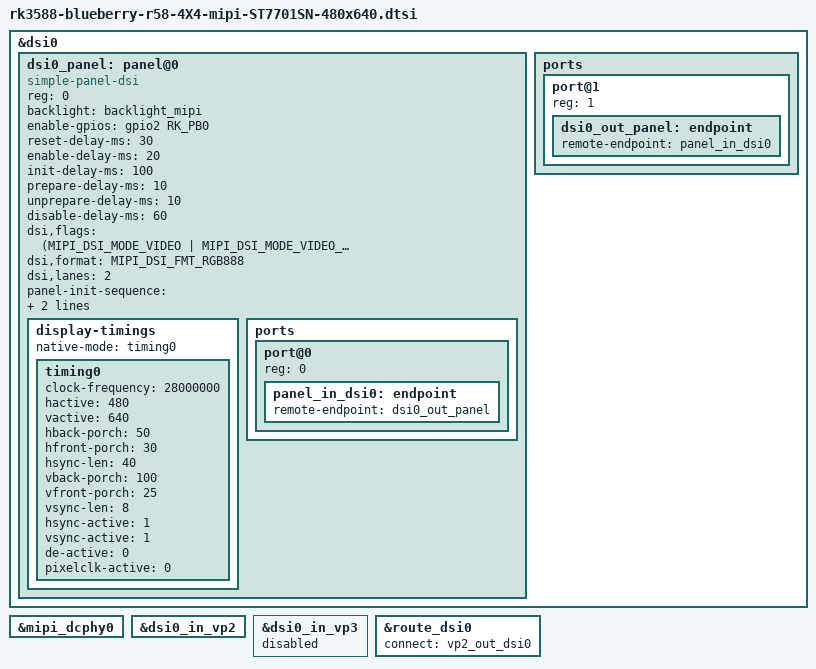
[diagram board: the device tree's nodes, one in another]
// SPDX-License-Identifier: (GPL-2.0+ OR MIT)
/*
 * Copyright (c) 2021 Rockchip Electronics Co., Ltd.
 *
 */

#include "dt-bindings/usb/pd.h"



&dsi0 {
	status = "okay";
	//rockchip,lane-rate = <1000>;
	dsi0_panel: panel@0 {
		status = "okay";
		compatible = "simple-panel-dsi";
		reg = <0>;
		backlight = <&backlight_mipi>;
		//power-supply = <&vcc3v3_mipi_lcd_power>;
		//reset-gpios =  <&gpio3 RK_PC4 GPIO_ACTIVE_LOW>; 
		enable-gpios = <&gpio2 RK_PB0 GPIO_ACTIVE_HIGH>;
		reset-delay-ms = <30>;
		enable-delay-ms = <20>;
		init-delay-ms = <100>;
		prepare-delay-ms = <10>;
		unprepare-delay-ms = <10>;
		disable-delay-ms = <60>;
		dsi,flags = <(MIPI_DSI_MODE_VIDEO | MIPI_DSI_MODE_VIDEO_BURST |
			MIPI_DSI_MODE_LPM | MIPI_DSI_MODE_EOT_PACKET)>;
		dsi,format = <MIPI_DSI_FMT_RGB888>;
		dsi,lanes  = <2>;

		panel-init-sequence = [
			29 00 06 FF 77 01 00 00 13
			23 00 02 EF 08
			29 00 06 FF 77 01 00 00 10
			29 00 03 C0 4F 00
			29 00 03 C1 10 02
			29 00 03 C2 07 02
			23 00 02 CC 10
			29 00 11 B0 00 10 17 0D 11 06 05 08 07 1F 04 11 0E 29 30 1F
			29 00 11 B1 00 0D 14 0E 11 06 04 08 08 20 05 13 13 26 30 1F
			29 00 06 FF 77 01 00 00 11
			23 00 02 B0 65
			23 00 02 B1 71
			23 00 02 B2 82
			23 00 02 B3 80
			23 00 02 B5 42
			23 00 02 B7 85
			23 00 02 B8 20			
			23 00 02 C0 09
			23 00 02 C1 78
			23 00 02 C2 78
			23 00 02 D0 88
			23 00 02 EE 42
			29 00 04 E0 00 00 02
			29 00 0C E1 04 A0 06 A0 05 A0 07 A0 00 44 44
			29 00 0D E2 00 00 00 00 00 00 00 00 00 00 00 00
			29 00 05 E3 00 00 22 22
			29 00 03 E4 44 44
			29 00 11 E5 0C 90 A0 A0 0E 92 A0 A0 08 8C A0 A0 0A 8E A0 A0
			29 00 05 E6 00 00 22 22
			29 00 03 E7 44 44
			29 00 11 E8 0D 91 A0 A0 0F 93 A0 A0 09 8D A0 A0 0B 8F A0 A0
			29 00 08 EB 00 00 E4 E4 44 00 40
			29 00 11 ED FF F5 47 6F 0B A1 AB FF FF BA 1A B0 F6 74 5F FF
			29 00 07 EF 08 08 08 40 3F 64
			29 00 06 FF 77 01 00 00 00
			29 00 06 FF 77 01 00 00 13
			29 00 03 E6 16 7C
			29 00 03 E8 00 0E
			29 00 06 FF 77 01 00 00 00
			05 78 01 11
			29 00 06 FF 77 01 00 00 13

			29 10 03 E8 00 0C
			29 10 03 E8 00 00
			29 00 06 FF 77 01 00 00 00
			05 00 01 29
			23 00 02 35 00

		];
		/*  //可以显示但有网格  2.8IPS_ADS(480X640)_ST7701S_FW(Customer)-190802.ini
				panel-init-sequence = [
			29 00 06 FF 77 01 00 00 13
			23 00 02 EF 08
			29 00 06 FF 77 01 00 00 10
			29 00 03 C0 4F 00
			29 00 03 C1 10 0C
			29 00 03 C2 01 14
			23 00 02 CC 10
			29 00 11 B0 0A 18 1E 12 16 0C 0E 0D 0C 29 06 14 13 29 33 1C
			29 00 11 B1 0A 19 21 0A 0C 00 0C 03 03 23 01 0E 0C 27 2B 1C
			29 00 06 FF 77 01 00 00 11
			23 00 02 B0 5D
			23 00 02 B1 4B
			23 00 02 B2 84
			23 00 02 B3 80
			23 00 02 B5 4D
			23 00 02 B7 85
			23 00 02 B8 20			
			23 00 02 C1 78
			23 00 02 C2 78
			23 00 02 D0 88
			29 00 04 E0 00 00 02
			29 00 0C E1 06 A0 08 A0 05 A0 07 A0 00 44 44
			29 00 0D E2 20 20 44 44 96 A0 00 00 96 A0 00 00
			29 00 05 E3 00 00 22 22
			29 00 03 E4 44 44
			29 00 11 E5 0D 91 A0 A0 0F 93 A0 A0 09 8D A0 A0 0B 8F A0 A0
			29 00 05 E6 00 00 22 22
			29 00 03 E7 44 44
			29 00 11 E8 0C 90 A0 A0 0E 92 A0 A0 08 8C A0 0A 0A 8E A0 A0
			29 00 03 E9 36 00
			29 00 08 EB 00 00 E4 E4 44 88 40
			29 00 11 ED FF 45 67 FA 01 2B CF FF FF FC B2 10 AF 76 54 FF
			29 00 07 EF 10 0D 04 08 3F 1F
			05 78 01 11
			23 00 02 36 00
			05 00 01 29
			23 00 02 35 00

		];*/

/*  //可以点亮，但是花屏
		panel-init-sequence = [
			29 00 06 FF 77 01 00 00 13
			23 00 02 EF 08
			29 00 06 FF 77 01 00 00 10
			29 00 03 C0 4F 00
			29 00 03 C1 10 02
			29 00 03 C2 07 02
			23 00 02 CC 10
			29 00 11 B0 00 10 17 0D 11 06 05 08 07 1F 04 11 0E 29 30 1F
			29 00 11 B1 00 0D 14 0E 11 06 04 08 08 20 05 13 13 26 30 1F
			29 00 06 FF 77 01 00 00 11
			23 00 02 B0 65
			23 00 02 B1 71
			23 00 02 B2 82
			23 00 02 B3 80
			23 00 02 B5 42
			23 00 02 B7 85
			23 00 02 B8 20			
			23 00 02 C0 09
			23 00 02 C1 78
			23 00 02 C2 78
			23 00 02 D0 88
			23 00 02 EE 42
			29 00 04 E0 00 00 02
			29 00 0C E1 04 A0 06 A0 05 A0 07 A0 00 44 44
			29 00 0D E2 00 00 00 00 00 00 00 00 00 00 00 00
			29 00 05 E3 00 00 22 22
			29 00 03 E4 44 44
			29 00 11 E5 0C 90 A0 A0 0E 92 A0 A0 08 8C A0 A0 0A 8E A0 A0
			29 00 05 E6 00 00 22 22
			29 00 03 E7 44 44
			29 00 11 E8 0D 91 A0 A0 0F 93 A0 A0 09 8D A0 A0 0B 8F A0 A0
			29 00 08 EB 00 00 E4 E4 44 00 40
			29 00 11 ED FF F5 47 6F 0B A1 AB FF FF BA 1A B0 F6 74 5F FF
			29 00 07 EF 08 08 08 40 3F 64
			29 00 06 FF 77 01 00 00 00
			29 00 06 FF 77 01 00 00 13
			29 00 03 E6 16 7C
			29 00 03 E8 00 0E
			29 00 06 FF 77 01 00 00 00
			05 78 01 11
			29 00 06 FF 77 01 00 00 13

			29 10 03 E8 00 0C
			29 10 03 E8 00 00
			29 00 06 FF 77 01 00 00 00
			05 00 01 29
			23 00 02 35 00
		];
		*/
/*
		panel-init-sequence = [
			29 00 06 FF 77 01 00 00 13
			23 00 02 EF 08
			29 00 06 FF 77 01 00 00 10
			29 00 03 C0 4F 00
			29 00 03 C1 10 02
			29 00 03 C2 07 02
			23 00 02 CC 10
			29 00 11 B0 00 10 17 0D 11 06 05 08 07 1F 04 11 0E 29 30 1F
			29 00 11 B1 00 0D 14 0E 11 06 04 08 08 20 05 13 13 26 30 1F
			29 00 06 FF 77 01 00 00 11
			23 00 02 B0 65
			23 00 02 B1 71
			23 00 02 B2 82
			23 00 02 B3 80
			23 00 02 B5 42
			23 00 02 B7 85
			23 00 02 B8 20			
			23 00 02 C0 09
			23 00 02 C1 78
			23 00 02 C2 78
			23 00 02 D0 88
			23 00 02 EE 42
			29 00 04 E0 00 00 02
			29 00 0C E1 04 A0 06 A0 05 A0 07 A0 00 44 44
			29 00 0D E2 00 00 00 00 00 00 00 00 00 00 00 00
			29 00 05 E3 00 00 22 22
			29 00 03 E4 44 44
			29 00 11 E5 0C 90 A0 A0 0E 92 A0 A0 08 8C A0 A0 0A 8E A0 A0
			29 00 05 E6 00 00 22 22
			29 00 03 E7 44 44
			29 00 11 E8 0D 91 A0 A0 0F 93 A0 A0 09 8D A0 A0 0B 8F A0 A0
			29 00 08 EB 00 00 E4 E4 44 00 40
			29 00 11 ED FF F5 47 6F 0B A1 AB FF FF BA 1A B0 F6 74 5F FF
			29 00 07 EF 08 08 08 40 3F 64
			29 00 06 FF 77 01 00 00 00
			29 00 06 FF 77 01 00 00 13
			29 00 03 E6 16 7C
			29 00 03 E8 00 0E
			29 00 06 FF 77 01 00 00 00
			05 78 01 11
			29 00 06 FF 77 01 00 00 13

			29 10 03 E8 00 0C
			29 10 03 E8 00 00
			29 00 06 FF 77 01 00 00 00
			05 00 01 29
			23 00 02 35 00
		];
		*/
/*
		panel-init-sequence = [
			29 00 06 FF 77 01 00 00 13
			29 00 03 E8 00 0E
			29 00 06 FF 77 01 00 00 00
			05 78 01 11
			29 00 06 FF 77 01 00 00 13
			29 0A 03 E8 00 0C
			29 00 03 E8 00 00
			29 00 06 FF 77 01 00 00 00
			29 00 06 FF 77 01 00 00 10
			29 00 03 C0 4F 00
			29 00 03 C1 07 02
			29 00 03 C2 31 05
			23 00 02 C6 01
			23 00 02 CC 38
			29 00 11 B0 00 0A 11 0C 10 05 00 08 08 1F 07 13 10 A9 30 18
			29 00 11 B1 00 0B 11 0D 0F 05 02 07 06 20 05 15 13 A9 30 18
			29 00 06 FF 77 01 00 00 11
			23 00 02 B0 53
			23 00 02 B1 60
			23 00 02 B2 87
			23 00 02 B3 80
			23 00 02 B5 49
			23 00 02 B7 85
			23 00 02 B8 21
			23 00 02 C1 78
			23 78 02 C2 78
			29 00 04 E0 00 00 02
			29 00 0C E1 03 A0 00 00 02 A0 00 00 00 33 33
			29 00 0D E2 22 22 33 33 88 A0 00 00 87 A0 00 00
			29 00 05 E3 00 00 22 22
			29 00 03 E4 44 44
			29 00 11 E5 04 84 A0 A0 06 86 A0 A0 08 88 A0 A0 0A 8A A0 A0
			29 00 05 E6 00 00 22 22
			29 00 03 E7 44 44
			29 00 11 E8 03 83 A0 A0 05 85 A0 A0 07 87 A0 A0 09 89 A0 A0
			29 00 08 EB 00 01 E4 E4 88 00 40
			29 00 03 EC 3C 01
			29 00 11 ED AB 89 76 54 02 FF FF FF FF FF FF 20 45 67 98 BA
			29 00 07 EF 08 08 08 08 3F 1F
			29 00 06 FF 77 01 00 00 00
			05 14 01 29
		];
*/
		panel-exit-sequence = [
		];

		display-timings {
			native-mode = <&timing0>;
			timing0: timing0 {
				clock-frequency = <28000000>;  //159391260  159747840
				hactive = <480>;
				vactive = <640>; 
				hback-porch = <50>; //50
				hfront-porch = <30>;//30
				hsync-len = <40>;//40
				vback-porch = <100>;//100
				vfront-porch = <25>;//25
				vsync-len = <8>;//8
				hsync-active = <1>;
				vsync-active = <1>;
				de-active = <0>;
				pixelclk-active = <0>;
				};
		};

		ports {
			#address-cells = <1>;
			#size-cells = <0>;

			port@0 {
				reg = <0>;
				panel_in_dsi0: endpoint {
					remote-endpoint = <&dsi0_out_panel>;
				};
			};
		};
	};

		ports {
			#address-cells = <1>;
			#size-cells = <0>;

			port@1 {
				reg = <1>;
				dsi0_out_panel: endpoint {
					remote-endpoint = <&panel_in_dsi0>;
				};
			};
		};
	
};

&dsi0 {
	status = "okay";
};

&mipi_dcphy0 {
	status = "okay";
};

&dsi0_in_vp2 {
	status = "okay";
};

&dsi0_in_vp3 {
	status = "disabled";
};

&route_dsi0 {
	status = "okay";
	connect = <&vp2_out_dsi0>;
};
